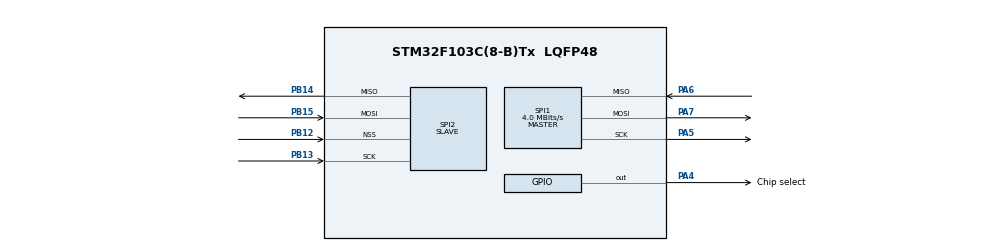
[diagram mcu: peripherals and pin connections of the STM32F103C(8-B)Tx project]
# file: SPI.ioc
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Mcu.Family=STM32F1
Mcu.Name=STM32F103C(8-B)Tx
Mcu.Package=LQFP48
NVIC.PriorityGroup=NVIC_PRIORITYGROUP_4
NVIC.SPI1_IRQn=true\:0\:0\:false\:false\:true\:true\:true\:true
NVIC.SPI2_IRQn=true\:0\:0\:false\:false\:true\:true\:true\:true
PA4.GPIO_Label=Chip select 
PA4.GPIO_PuPd=GPIO_NOPULL
PA4.PinState=GPIO_PIN_SET
PA4.Signal=GPIO_Output
PA5.Mode=Full_Duplex_Master
PA5.Signal=SPI1_SCK
PA6.Mode=Full_Duplex_Master
PA6.Signal=SPI1_MISO
PA7.Mode=Full_Duplex_Master
PA7.Signal=SPI1_MOSI
PB12.Mode=NSS_Signal_Hard_Input
PB12.Signal=SPI2_NSS
PB13.Mode=Full_Duplex_Slave
PB13.Signal=SPI2_SCK
PB14.Mode=Full_Duplex_Slave
PB14.Signal=SPI2_MISO
PB15.Mode=Full_Duplex_Slave
PB15.Signal=SPI2_MOSI
ProjectManager.HeapSize=0x200
ProjectManager.StackSize=0x400
ProjectManager.TargetToolchain=STM32CubeIDE
RCC.APB1Freq_Value=8000000
RCC.APB2Freq_Value=8000000
SPI1.CalculateBaudRate=4.0 MBits/s
SPI1.Direction=SPI_DIRECTION_2LINES
SPI1.Mode=SPI_MODE_MASTER
SPI1.VirtualType=VM_MASTER
SPI2.Direction=SPI_DIRECTION_2LINES
SPI2.Mode=SPI_MODE_SLAVE
SPI2.VirtualNSS=VM_NSSHARD
SPI2.VirtualType=VM_SLAVE
VP_SYS_VS_ND.Mode=No_Debug
board=custom

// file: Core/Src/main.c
/* USER CODE BEGIN Header */
/**
  ******************************************************************************
  * @file           : main.c
  * @brief          : Main program body
  ******************************************************************************
  * @attention
  *
  * Copyright (c) 2024 STMicroelectronics.
  * All rights reserved.
  *
  * This software is licensed under terms that can be found in the LICENSE file
  * in the root directory of this software component.
  * If no LICENSE file comes with this software, it is provided AS-IS.
  *
  ******************************************************************************
  */
/* USER CODE END Header */
#include "main.h"

SPI_HandleTypeDef hspi1;
SPI_HandleTypeDef hspi2;

void SystemClock_Config(void);
static void MX_GPIO_Init(void);
static void MX_SPI1_Init(void);
static void MX_SPI2_Init(void);
/* USER CODE BEGIN PFP */
uint8_t u8SPI_Tx_Buffer[20] = "Master send!!";
uint8_t u8SPI_Rx_Buffer[20];
uint8_t u8Count;

/* USER CODE END PFP */

/*
  * @brief  The application entry point.
  * @retval int
  */
int main(void)
{

  /* MCU Configuration--------------------------------------------------------*/

  /* Reset of all peripherals, Initializes the Flash interface and the Systick. */
  HAL_Init();

  /* Configure the system clock */
  SystemClock_Config();

  /* Initialize all configured peripherals */
  MX_GPIO_Init();
  MX_SPI1_Init();
  MX_SPI2_Init();
  /* USER CODE BEGIN 2 */
  HAL_SPI_Receive_IT(&hspi2, u8SPI_Rx_Buffer, 20);
  HAL_SPI_Transmit(&hspi1, u8SPI_Tx_Buffer, 20, 100);
  /* USER CODE END 2 */

  /* Infinite loop */
  while (1)
  {

    sprintf((char*)u8SPI_Tx_Buffer,"Gui lan thu : %d /n",u8Count);
    HAL_GPIO_WritePin(Chip_select_GPIO_Port, Chip_select_Pin, RESET);
    HAL_SPI_Transmit(&hspi1, u8SPI_Tx_Buffer, 20, 100);
    HAL_GPIO_WritePin(Chip_select_GPIO_Port, Chip_select_Pin, SET);
    HAL_Delay(1000);
    u8Count++;
  }
}

void SystemClock_Config(void)
{
  RCC_OscInitTypeDef RCC_OscInitStruct = {0};
  RCC_ClkInitTypeDef RCC_ClkInitStruct = {0};

  /** Initializes the RCC Oscillators according to the specified parameters
  * in the RCC_OscInitTypeDef structure.
  */
  RCC_OscInitStruct.OscillatorType = RCC_OSCILLATORTYPE_HSI;
  RCC_OscInitStruct.HSIState = RCC_HSI_ON;
  RCC_OscInitStruct.HSICalibrationValue = RCC_HSICALIBRATION_DEFAULT;
  RCC_OscInitStruct.PLL.PLLState = RCC_PLL_NONE;
  if (HAL_RCC_OscConfig(&RCC_OscInitStruct) != HAL_OK)
  {
    Error_Handler();
  }

  /** Initializes the CPU, AHB and APB buses clocks
  */
  RCC_ClkInitStruct.ClockType = RCC_CLOCKTYPE_HCLK|RCC_CLOCKTYPE_SYSCLK
                              |RCC_CLOCKTYPE_PCLK1|RCC_CLOCKTYPE_PCLK2;
  RCC_ClkInitStruct.SYSCLKSource = RCC_SYSCLKSOURCE_HSI;
  RCC_ClkInitStruct.AHBCLKDivider = RCC_SYSCLK_DIV1;
  RCC_ClkInitStruct.APB1CLKDivider = RCC_HCLK_DIV1;
  RCC_ClkInitStruct.APB2CLKDivider = RCC_HCLK_DIV1;

  if (HAL_RCC_ClockConfig(&RCC_ClkInitStruct, FLASH_LATENCY_0) != HAL_OK)
  {
    Error_Handler();
  }
}

static void MX_SPI1_Init(void)
{

  /* SPI1 parameter configuration*/
  hspi1.Instance = SPI1;
  hspi1.Init.Mode = SPI_MODE_MASTER;
  hspi1.Init.Direction = SPI_DIRECTION_2LINES;
  hspi1.Init.DataSize = SPI_DATASIZE_8BIT;
  hspi1.Init.CLKPolarity = SPI_POLARITY_LOW;
  hspi1.Init.CLKPhase = SPI_PHASE_1EDGE;
  hspi1.Init.NSS = SPI_NSS_SOFT;
  hspi1.Init.BaudRatePrescaler = SPI_BAUDRATEPRESCALER_2;
  hspi1.Init.FirstBit = SPI_FIRSTBIT_MSB;
  hspi1.Init.TIMode = SPI_TIMODE_DISABLE;
  hspi1.Init.CRCCalculation = SPI_CRCCALCULATION_DISABLE;
  hspi1.Init.CRCPolynomial = 10;
  if (HAL_SPI_Init(&hspi1) != HAL_OK)
  {
    Error_Handler();
  }

}

static void MX_SPI2_Init(void)
{

  /* SPI2 parameter configuration*/
  hspi2.Instance = SPI2;
  hspi2.Init.Mode = SPI_MODE_SLAVE;
  hspi2.Init.Direction = SPI_DIRECTION_2LINES;
  hspi2.Init.DataSize = SPI_DATASIZE_8BIT;
  hspi2.Init.CLKPolarity = SPI_POLARITY_LOW;
  hspi2.Init.CLKPhase = SPI_PHASE_1EDGE;
  hspi2.Init.NSS = SPI_NSS_HARD_INPUT;
  hspi2.Init.FirstBit = SPI_FIRSTBIT_MSB;
  hspi2.Init.TIMode = SPI_TIMODE_DISABLE;
  hspi2.Init.CRCCalculation = SPI_CRCCALCULATION_DISABLE;
  hspi2.Init.CRCPolynomial = 10;
  if (HAL_SPI_Init(&hspi2) != HAL_OK)
  {
    Error_Handler();
  }

}

static void MX_GPIO_Init(void)
{
  GPIO_InitTypeDef GPIO_InitStruct = {0};

  /* GPIO Ports Clock Enable */
  __HAL_RCC_GPIOA_CLK_ENABLE();
  __HAL_RCC_GPIOB_CLK_ENABLE();

  /*Configure GPIO pin Output Level */
  HAL_GPIO_WritePin(Chip_select_GPIO_Port, Chip_select_Pin, GPIO_PIN_SET);

  /*Configure GPIO pin : Chip_select_Pin */
  GPIO_InitStruct.Pin = Chip_select_Pin;
  GPIO_InitStruct.Mode = GPIO_MODE_OUTPUT_PP;
  GPIO_InitStruct.Pull = GPIO_NOPULL;
  GPIO_InitStruct.Speed = GPIO_SPEED_FREQ_LOW;
  HAL_GPIO_Init(Chip_select_GPIO_Port, &GPIO_InitStruct);

}

void Error_Handler(void)
{
  __disable_irq();
  while (1)
  {
  }
}
